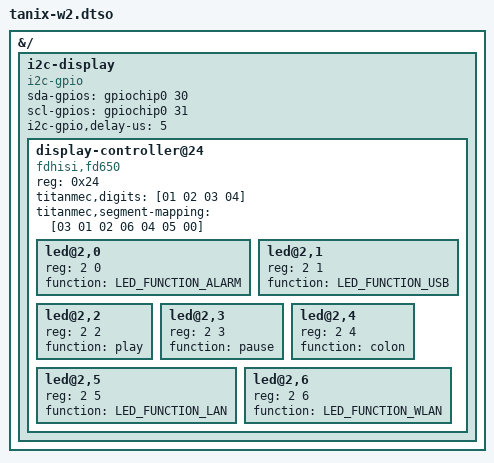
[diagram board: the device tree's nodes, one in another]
/dts-v1/;
/plugin/;

#include <dt-bindings/gpio/gpio.h>
#include <dt-bindings/leds/common.h>

&{/} {

	i2c-display {
		compatible = "i2c-gpio";
		sda-gpios = <&gpiochip0 30 (GPIO_ACTIVE_HIGH | GPIO_OPEN_DRAIN)>;
		scl-gpios = <&gpiochip0 31 (GPIO_ACTIVE_HIGH | GPIO_OPEN_DRAIN)>;
		i2c-gpio,delay-us = <5>;
		#address-cells = <1>;
		#size-cells = <0>;

		display-controller@24 {
			compatible = "fdhisi,fd650";
			reg = <0x24>;

			titanmec,digits = [01 02 03 04];
			titanmec,segment-mapping = [03 01 02 06 04 05 00];

			#address-cells = <2>;
			#size-cells = <0>;
			
			led@2,0 {
				reg = <2 0>;
				function = LED_FUNCTION_ALARM;
			};
			
			led@2,1 {
				reg = <2 1>;
				function = LED_FUNCTION_USB;
			};
			
			led@2,2 {
				reg = <2 2>;
				function = "play";
			};
			
			led@2,3 {
				reg = <2 3>;
				function = "pause";
			};
			
			led@2,4 {
				reg = <2 4>;
				function = "colon";
			};
			
			led@2,5 {
				reg = <2 5>;
				function = LED_FUNCTION_LAN;
			};
			
			led@2,6 {
				reg = <2 6>;
				function = LED_FUNCTION_WLAN;
			};

		};
	};
};

